# apollo5b register map
Vendor: Ambiq Micro; Series: Apollo; File version: 1.0
CPU: CM55 r1p1, little endian, MPU, FPU, double-precision FPU, DSP, I-cache, D-cache, VTOR, ITCM, DTCM, 4 interrupt priority bits, 0 interrupts, 8 SAU regions
Registers are 32-bit, read-write, reset 0x0 unless marked. A register's access mark holds for its fields unless they carry their own. Offsets are from the block's base; [hi:lo] are bit positions; 'fields as' and 'values as' point back to an identical list.

## RSTGEN — MCU Reset Generator
Base 0x40000000
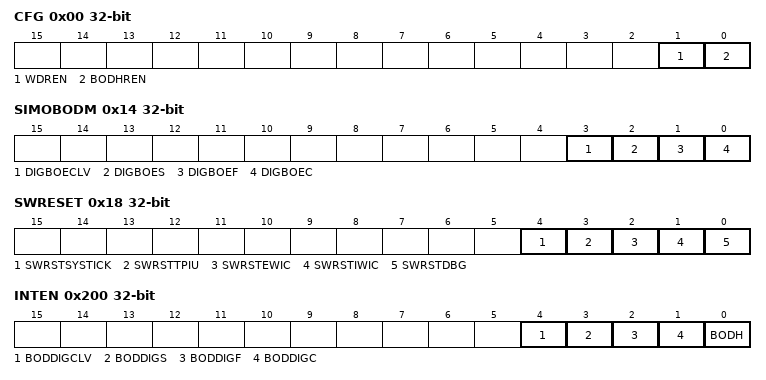
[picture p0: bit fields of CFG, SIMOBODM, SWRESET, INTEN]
0x00 CFG — Reset configuration register. This controls the reset enables for brownout condition, choice of brownout method and for the expiration of the watch dog timer.
  [1] WDREN — Watchdog Timer Reset Enable. NOTE: The WDT module must also be configured for WDT reset. This includes enabling the RESEN bit in WDTCFG register in Watch dog timer block.
  [0] BODHREN — Brown out high (2.1v) reset enable.
0x04 SWPOI — This is the software POI reset. writing the key value to this register will trigger a POI to the system. This will cause a reset to all blocks except for registers in clock gen, RTC and the stimer.
  [7:0] SWPOIKEY — 0x1B generates a software POI reset. This is a write-only register. Reading from this register will yield only all 0s.
    27=KEYVALUE (Writing 0x1B key value generates a software POI reset.); 0=DEFAULT (Default value.)
0x08 SWPOR — This is the software POR reset. Writing the key value to this register will trigger a POR to the system. This will cause a reset to all blocks except for registers in clock gen, RTC, power management unit, the stimer, and the power management unit.
  [7:0] SWPORKEY — 0xD4 generates a software POR reset.
    212=KEYVALUE (Writing 0xD4 key value generates a software POR reset.); 0=DEFAULT (Default value.)
0x14 SIMOBODM — This register unmasks the individual digital detection brownout bits into the interrupt block
  [3] DIGBOECLV — Enable the gate into the interrupt block for the digital brownout detection on VDDC_LV. Note: The interrupt block must also be unmasked for ISR and interrupt status to be set
    0=BOM (Mask the VDDC_LV digital brownout detection into the interrupt block.); 1=BOE (Enable brown VDDC_LV digital brownout detection into the interrupt block.)
  [2] DIGBOES — Enable the gate into the interrupt block for the digital brownout detection on VDDS. Note: The interrupt block must also be unmasked for ISR and interrupt status to be set
    0=BOM (Mask the VDDS digital brownout detection into the interrupt block.); 1=BOE (Enable the VDDS digital brownout detection into the interrupt block.)
  [1] DIGBOEF — Enable the gate into the interrupt block for the digital brownout detection on VDDF. Note: The interrupt block must also be unmasked for ISR and interrupt status to be set
    0=BOM (Mask the VDDF digital brownout detection into the interrupt block.); 1=BOE (Enable the VDDF digital brownout detection into the interrupt block.)
  [0] DIGBOEC — Enable the gate into the interrupt block for the digital brownout detection on VDDC. Note: The interrupt block must also be unmasked for ISR and interrupt status to be set
    0=BOA (Enable brown out detection for VDDF using the analog method.); 1=BOD (Enable brown out detection for VDDF using the digital method.)
0x18 SWRESET — Software reset register
  [4] SWRSTSYSTICK — Software reset for SysTick
    0=NORMALOP (Normal operation); 1=RESET (Hold SysTick feature in reset)
  [3] SWRSTTPIU — Software reset for TPIU
    0=NORMALOP (Normal operation); 1=RESET (Hold TPIU feature in reset)
  [2] SWRSTEWIC — Reserved field.
  [1] SWRSTIWIC — Software reset for IWIC
    0=NORMALOP (Normal operation); 1=RESET (Hold IWIC feature in reset)
  [0] SWRSTDBG — Software reset for DEBUG
    0=NORMALOP (Normal operation); 1=RESET (Hold DEBUG feature in reset)
0x200 INTEN — Set bits in this register to allow this module to generate the corresponding interrupt.
  [4] BODDIGCLV — Enables an interrupt that triggers when simobuck digital detects inactivity on VDDC_LV
  [3] BODDIGS — Enables an interrupt that triggers when simobuck digital detects inactivity on VDDS
  [2] BODDIGF — Enables an interrupt that triggers when simobuck digital detects inactivity on VDDF
  [1] BODDIGC — Enables an interrupt that triggers when simobuck digital detects inactivity on VDDC
  [0] BODH — Enables an interrupt that triggers when VCC is below BODH level.
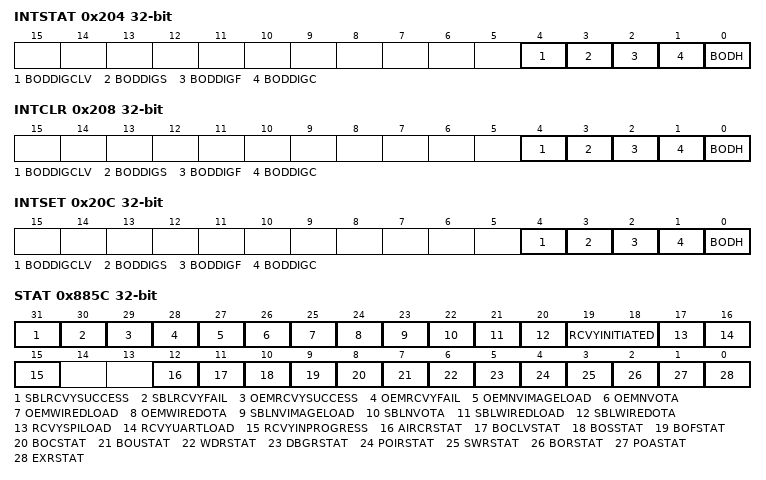
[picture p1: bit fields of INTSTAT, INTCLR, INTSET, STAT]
0x204 INTSTAT — Read bits from this register to discover the cause of a recent interrupt.
  fields as INTEN
0x208 INTCLR — Write a 1 to a bit in this register to clear the interrupt status associated with that bit.
  fields as INTEN
0x20C INTSET — Write a 1 to a bit in this register to instantly generate an interrupt from this module. (Generally used for testing purposes).
  fields as INTEN
0x885C STAT — This register contains information about the status of and causes for resets and brownouts. NOTE 1: The bootrom and/or the secure bootloader maintain and update this register with appropriate status after each reset event. NOTE 2: While this register is intended to be read-only, all bits in this register, including reserved bits, are in fact writable. Therefore SW should take great care to never write this register.
  [31] SBLRCVYSUCCESS — SBL recovery was successful by Secure Bootrom.
  [30] SBLRCVYFAIL — SBL recovery was attempted but failed.
  [29] OEMRCVYSUCCESS — OEM recovery was successful.
  [28] OEMRCVYFAIL — OEM recovery was attempted but failed.
  [27] OEMNVIMAGELOAD — OEM recovery detailed status: NV Image Load was successful.
  [26] OEMNVOTA — OEM recovery detailed status: NV OTA was successful.
  [25] OEMWIREDLOAD — OEM recovery detailed status: wired load was successful.
  [24] OEMWIREDOTA — OEM recovery detailed status: wired OTA was successful.
  [23] SBLNVIMAGELOAD — SBL recovery detailed status: NV Image Load was successful.
  [22] SBLNVOTA — SBL recovery detailed status: NV OTA was successful.
  [21] SBLWIREDLOAD — SBL recovery detailed status: wired load was successful.
  [20] SBLWIREDOTA — SBL recovery detailed status: wired OTA was successful.
  [19:18] RCVYINITIATED — A recovery event was initiated by one of the following: APP, GPIO, or certificate error.
    3=OEM (Recovery was initiated because OEM certification failed.); 2=ICV (Recovery was initiated because ICV certification failed.); 1=GPIO (Recovery was initiated by GPIO.); 0=APPREQ (Recovery was requested by the application.)
  [17] RCVYSPILOAD — The recovery image loaded via SPI.
  [16] RCVYUARTLOAD — The recovery image loaded via UART.
  [15] RCVYINPROGRESS — An MRAM recovery operation is in progress.
  [12] AIRCRSTAT — System reset request (SYSRESETREQ from CM55)
  [11] BOCLVSTAT — VDDC_LV Analog Brownout Event occurred.
  [10] BOSSTAT — VDDS Analog Brownout Event occurred.
  [9] BOFSTAT — VDDF Analog Brownout Event occurred.
  [8] BOCSTAT — VDDC Analog Brownout Event occurred.
  [7] BOUSTAT — An Unregulated Supply Brownout Event occurred.
  [6] WDRSTAT — Reset was initiated by a Watchdog Timer Reset.
  [5] DBGRSTAT — Reset was a initiated by Debugger Reset.
  [4] POIRSTAT — Reset was a initiated by Software POI Reset.
  [3] SWRSTAT — Reset was a initiated by SW POR Reset.
  [2] BORSTAT — Reset was initiated by a Brown-Out Reset. Following powerup, this bit may be inadvertantly set due to the Brown-Out signals powering up in a unusual sequence. It is recommended to clear this bit after initial powerup.
  [1] POASTAT — Reset was initiated by a Power-On Analog (POA) Reset.
  [0] EXRSTAT — Reset was initiated by an External Reset.
